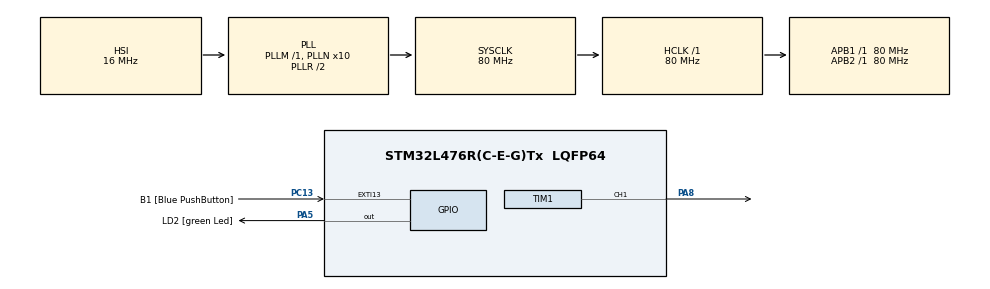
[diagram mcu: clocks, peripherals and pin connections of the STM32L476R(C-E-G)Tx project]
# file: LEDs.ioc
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Dma.Request0=TIM1_CH1
Dma.TIM1_CH1.0.Direction=DMA_MEMORY_TO_PERIPH
Dma.TIM1_CH1.0.Instance=DMA1_Channel2
Dma.TIM1_CH1.0.MemDataAlignment=DMA_MDATAALIGN_HALFWORD
Dma.TIM1_CH1.0.MemInc=DMA_MINC_ENABLE
Dma.TIM1_CH1.0.Mode=DMA_NORMAL
Dma.TIM1_CH1.0.PeriphDataAlignment=DMA_PDATAALIGN_HALFWORD
Dma.TIM1_CH1.0.PeriphInc=DMA_PINC_DISABLE
Dma.TIM1_CH1.0.Priority=DMA_PRIORITY_HIGH
Mcu.Family=STM32L4
Mcu.Name=STM32L476R(C-E-G)Tx
Mcu.Package=LQFP64
NVIC.DMA1_Channel2_IRQn=true\:0\:0\:false\:false\:true\:false\:true\:true
NVIC.PriorityGroup=NVIC_PRIORITYGROUP_4
PA13\ (JTMS-SWDIO).GPIO_Label=TMS
PA13\ (JTMS-SWDIO).Signal=SYS_JTMS-SWDIO
PA14\ (JTCK-SWCLK).GPIO_Label=TCK
PA14\ (JTCK-SWCLK).Signal=SYS_JTCK-SWCLK
PA2.GPIO_Label=USART_TX
PA2.GPIO_Mode=GPIO_MODE_AF_PP
PA2.GPIO_PuPd=GPIO_NOPULL
PA2.GPIO_Speed=GPIO_SPEED_FREQ_VERY_HIGH
PA2.Signal=USART2_TX
PA3.GPIO_Label=USART_RX
PA3.GPIO_Mode=GPIO_MODE_AF_PP
PA3.GPIO_PuPd=GPIO_NOPULL
PA3.GPIO_Speed=GPIO_SPEED_FREQ_VERY_HIGH
PA3.Signal=USART2_RX
PA5.GPIO_Label=LD2 [green Led]
PA5.GPIO_ModeDefaultOutputPP=GPIO_MODE_OUTPUT_PP
PA5.GPIO_PuPd=GPIO_NOPULL
PA5.GPIO_Speed=GPIO_SPEED_FREQ_LOW
PA5.Signal=GPIO_Output
PA8.GPIO_Speed=GPIO_SPEED_FREQ_VERY_HIGH
PA8.Signal=S_TIM1_CH1
PB3\ (JTDO-TRACESWO).GPIO_Label=SWO
PB3\ (JTDO-TRACESWO).Signal=SYS_JTDO-SWO
PC13.GPIO_Label=B1 [Blue PushButton]
PC13.GPIO_ModeDefaultEXTI=GPIO_MODE_IT_FALLING
PC13.GPIO_PuPd=GPIO_NOPULL
PC13.Signal=GPXTI13
PC14-OSC32_IN\ (PC14).Signal=RCC_OSC32_IN
PC15-OSC32_OUT\ (PC15).Signal=RCC_OSC32_OUT
PH0-OSC_IN\ (PH0).Signal=RCC_OSC_IN
PH1-OSC_OUT\ (PH1).Signal=RCC_OSC_OUT
ProjectManager.HeapSize=0x200
ProjectManager.StackSize=0x400
ProjectManager.TargetToolchain=STM32CubeIDE
RCC.ADCFreq_Value=64000000
RCC.AHBFreq_Value=80000000
RCC.APB1Freq_Value=80000000
RCC.APB1TimFreq_Value=80000000
RCC.APB2Freq_Value=80000000
RCC.APB2TimFreq_Value=80000000
RCC.CortexFreq_Value=80000000
RCC.HCLKFreq_Value=80000000
RCC.HSE_VALUE=8000000
RCC.HSI_VALUE=16000000
RCC.LSE_VALUE=32768
RCC.MSI_VALUE=4000000
RCC.PLLN=10
RCC.PLLSourceVirtual=RCC_PLLSOURCE_HSI
RCC.PREFETCH_ENABLE=1
RCC.SYSCLKFreq_VALUE=80000000
RCC.SYSCLKSource=RCC_SYSCLKSOURCE_PLLCLK
RCC.USBFreq_Value=64000000
RCC.VCOOutputFreq_Value=160000000
SH.S_TIM1_CH1.0=TIM1_CH1,PWM Generation1 CH1
TIM1.AutoReloadPreload=TIM_AUTORELOAD_PRELOAD_ENABLE
TIM1.Channel-PWM\ Generation1\ CH1=TIM_CHANNEL_1
TIM1.Period=99
VP_TIM1_VS_ClockSourceINT.Mode=Internal
board=NUCLEO-L476RG

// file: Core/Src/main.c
/* USER CODE BEGIN Header */
/**
  ******************************************************************************
  * @file           : main.c
  * @brief          : Main program body
  ******************************************************************************
  */
/* USER CODE END Header */
#include "main.h"

/* USER CODE BEGIN Includes */
#include <string.h>   // pour memset
/* USER CODE END Includes */

/* USER CODE BEGIN PD */
// === Config NeoPixel ===
#define LED_COUNT    8
#define BITS_PER_LED 24
#define RESET_TICKS  100

// 80 MHz timer -> 1 bit = 1.25 µs = 100 ticks (ARR=99)
#define ARR_VALUE   99
#define T0H_TICKS   32   // ~0.40 µs (bit 0)
#define T1H_TICKS   64   // ~0.80 µs (bit 1)
/* USER CODE END PD */

TIM_HandleTypeDef htim1;
DMA_HandleTypeDef hdma_tim1_ch1;

/* USER CODE BEGIN PV */
static uint16_t pwm_buf[LED_COUNT * BITS_PER_LED + RESET_TICKS];
static uint8_t  leds[LED_COUNT][3]; // [G,R,B]
/* USER CODE END PV */

void SystemClock_Config(void);
static void MX_GPIO_Init(void);
static void MX_DMA_Init(void);
static void MX_TIM1_Init(void);
/* USER CODE BEGIN PFP */
// Fonctions NeoPixel
static void byte_to_pwm(uint8_t byte, uint16_t *out);
void np_set_pixel(uint16_t i, uint8_t r, uint8_t g, uint8_t b);
void np_clear(void);
void np_show(void);
/* USER CODE END PFP */

/* USER CODE BEGIN 0 */
static void byte_to_pwm(uint8_t byte, uint16_t *out)
{
  for (int i = 0; i < 8; i++) {
    out[i] = (byte & (1 << (7 - i))) ? T1H_TICKS : T0H_TICKS;
  }
}

void np_set_pixel(uint16_t i, uint8_t r, uint8_t g, uint8_t b)
{
  if (i >= LED_COUNT) return;
  leds[i][0] = g; // ordre GRB
  leds[i][1] = r;
  leds[i][2] = b;
}

void np_clear(void)
{
  memset(leds, 0, sizeof(leds));
}

void np_show(void)
{
  uint16_t *p = pwm_buf;
  for (int i = 0; i < LED_COUNT; i++) {
    byte_to_pwm(leds[i][0], p); p += 8; // G
    byte_to_pwm(leds[i][1], p); p += 8; // R
    byte_to_pwm(leds[i][2], p); p += 8; // B
  }
  for (int i = 0; i < RESET_TICKS; i++) *p++ = 0;

  __HAL_TIM_SET_AUTORELOAD(&htim1, ARR_VALUE);

  HAL_TIM_PWM_Start_DMA(&htim1, TIM_CHANNEL_1,
                        (uint32_t*)pwm_buf, (uint32_t)(p - pwm_buf));

  // Attendre la fin du DMA
  while (hdma_tim1_ch1.State != HAL_DMA_STATE_READY) { }

  HAL_TIM_PWM_Stop_DMA(&htim1, TIM_CHANNEL_1);
}
/* USER CODE END 0 */

int main(void)
{
  /* MCU Configuration--------------------------------------------------------*/
  HAL_Init();
  SystemClock_Config();
  MX_GPIO_Init();
  MX_DMA_Init();
  MX_TIM1_Init();

  /* USER CODE BEGIN 2 */

  np_clear();
  np_set_pixel(0, 255,   0,   0); // Rouge
  np_set_pixel(1,   0, 255,   0); // Vert
  np_set_pixel(2,   0,   0, 255); // Bleu
  np_set_pixel(3, 255, 255,   0); // Jaune
  np_set_pixel(4, 255,   0,   0); // Rouge
  np_set_pixel(5,   0, 255,   0); // Vert
  np_set_pixel(6,   0,   0, 255); // Bleu
  np_set_pixel(7, 255, 255,   0); // Jaune
  np_show();

  /* USER CODE END 2 */

  while (1)
  {
    /* USER CODE BEGIN WHILE */
    // boucle principale
	  for (int pos = 0; pos < LED_COUNT; pos++) {
	    np_clear();

	    // rouge
	    np_set_pixel(pos, 255, 0, 0);
	    np_show();
	    HAL_Delay(200);

	    // vert
	    np_clear();
	    np_set_pixel(pos, 0, 255, 0);
	    np_show();
	    HAL_Delay(200);

	    // bleu
	    np_clear();
	    np_set_pixel(pos, 0, 0, 255);
	    np_show();
	    HAL_Delay(200);
	  }
    /* USER CODE END WHILE */

    /* USER CODE BEGIN 3 */
  }
}

void SystemClock_Config(void)
{
  RCC_OscInitTypeDef RCC_OscInitStruct = {0};
  RCC_ClkInitTypeDef RCC_ClkInitStruct = {0};

  if (HAL_PWREx_ControlVoltageScaling(PWR_REGULATOR_VOLTAGE_SCALE1) != HAL_OK)
  {
    Error_Handler();
  }
  RCC_OscInitStruct.OscillatorType = RCC_OSCILLATORTYPE_HSI;
  RCC_OscInitStruct.HSIState = RCC_HSI_ON;
  RCC_OscInitStruct.HSICalibrationValue = RCC_HSICALIBRATION_DEFAULT;
  RCC_OscInitStruct.PLL.PLLState = RCC_PLL_ON;
  RCC_OscInitStruct.PLL.PLLSource = RCC_PLLSOURCE_HSI;
  RCC_OscInitStruct.PLL.PLLM = 1;
  RCC_OscInitStruct.PLL.PLLN = 10;
  RCC_OscInitStruct.PLL.PLLP = RCC_PLLP_DIV7;
  RCC_OscInitStruct.PLL.PLLQ = RCC_PLLQ_DIV2;
  RCC_OscInitStruct.PLL.PLLR = RCC_PLLR_DIV2;
  if (HAL_RCC_OscConfig(&RCC_OscInitStruct) != HAL_OK)
  {
    Error_Handler();
  }
  RCC_ClkInitStruct.ClockType = RCC_CLOCKTYPE_HCLK|RCC_CLOCKTYPE_SYSCLK
                              |RCC_CLOCKTYPE_PCLK1|RCC_CLOCKTYPE_PCLK2;
  RCC_ClkInitStruct.SYSCLKSource = RCC_SYSCLKSOURCE_PLLCLK;
  RCC_ClkInitStruct.AHBCLKDivider = RCC_SYSCLK_DIV1;
  RCC_ClkInitStruct.APB1CLKDivider = RCC_HCLK_DIV1;
  RCC_ClkInitStruct.APB2CLKDivider = RCC_HCLK_DIV1;

  if (HAL_RCC_ClockConfig(&RCC_ClkInitStruct, FLASH_LATENCY_4) != HAL_OK)
  {
    Error_Handler();
  }
}

static void MX_TIM1_Init(void)
{
  TIM_ClockConfigTypeDef sClockSourceConfig = {0};
  TIM_MasterConfigTypeDef sMasterConfig = {0};
  TIM_OC_InitTypeDef sConfigOC = {0};
  TIM_BreakDeadTimeConfigTypeDef sBreakDeadTimeConfig = {0};

  htim1.Instance = TIM1;
  htim1.Init.Prescaler = 0;
  htim1.Init.CounterMode = TIM_COUNTERMODE_UP;
  htim1.Init.Period = 99;
  htim1.Init.ClockDivision = TIM_CLOCKDIVISION_DIV1;
  htim1.Init.RepetitionCounter = 0;
  htim1.Init.AutoReloadPreload = TIM_AUTORELOAD_PRELOAD_ENABLE;
  if (HAL_TIM_Base_Init(&htim1) != HAL_OK) Error_Handler();
  sClockSourceConfig.ClockSource = TIM_CLOCKSOURCE_INTERNAL;
  if (HAL_TIM_ConfigClockSource(&htim1, &sClockSourceConfig) != HAL_OK) Error_Handler();
  if (HAL_TIM_PWM_Init(&htim1) != HAL_OK) Error_Handler();
  sMasterConfig.MasterOutputTrigger = TIM_TRGO_RESET;
  sMasterConfig.MasterOutputTrigger2 = TIM_TRGO2_RESET;
  sMasterConfig.MasterSlaveMode = TIM_MASTERSLAVEMODE_DISABLE;
  if (HAL_TIMEx_MasterConfigSynchronization(&htim1, &sMasterConfig) != HAL_OK) Error_Handler();
  sConfigOC.OCMode = TIM_OCMODE_PWM1;
  sConfigOC.Pulse = 0;
  sConfigOC.OCPolarity = TIM_OCPOLARITY_HIGH;
  sConfigOC.OCNPolarity = TIM_OCNPOLARITY_HIGH;
  sConfigOC.OCFastMode = TIM_OCFAST_DISABLE;
  sConfigOC.OCIdleState = TIM_OCIDLESTATE_RESET;
  sConfigOC.OCNIdleState = TIM_OCNIDLESTATE_RESET;
  if (HAL_TIM_PWM_ConfigChannel(&htim1, &sConfigOC, TIM_CHANNEL_1) != HAL_OK) Error_Handler();
  sBreakDeadTimeConfig.OffStateRunMode = TIM_OSSR_DISABLE;
  sBreakDeadTimeConfig.OffStateIDLEMode = TIM_OSSI_DISABLE;
  sBreakDeadTimeConfig.LockLevel = TIM_LOCKLEVEL_OFF;
  sBreakDeadTimeConfig.DeadTime = 0;
  sBreakDeadTimeConfig.BreakState = TIM_BREAK_DISABLE;
  sBreakDeadTimeConfig.BreakPolarity = TIM_BREAKPOLARITY_HIGH;
  sBreakDeadTimeConfig.BreakFilter = 0;
  sBreakDeadTimeConfig.Break2State = TIM_BREAK2_DISABLE;
  sBreakDeadTimeConfig.Break2Polarity = TIM_BREAK2POLARITY_HIGH;
  sBreakDeadTimeConfig.Break2Filter = 0;
  sBreakDeadTimeConfig.AutomaticOutput = TIM_AUTOMATICOUTPUT_DISABLE;
  if (HAL_TIMEx_ConfigBreakDeadTime(&htim1, &sBreakDeadTimeConfig) != HAL_OK) Error_Handler();

  HAL_TIM_MspPostInit(&htim1);
}

static void MX_DMA_Init(void)
{
  __HAL_RCC_DMA1_CLK_ENABLE();
  HAL_NVIC_SetPriority(DMA1_Channel2_IRQn, 0, 0);
  HAL_NVIC_EnableIRQ(DMA1_Channel2_IRQn);
}

static void MX_GPIO_Init(void)
{
  GPIO_InitTypeDef GPIO_InitStruct = {0};
  __HAL_RCC_GPIOC_CLK_ENABLE();
  __HAL_RCC_GPIOH_CLK_ENABLE();
  __HAL_RCC_GPIOA_CLK_ENABLE();
  __HAL_RCC_GPIOB_CLK_ENABLE();

  // Exemple: LED verte LD2
  HAL_GPIO_WritePin(LD2_GPIO_Port, LD2_Pin, GPIO_PIN_RESET);
  GPIO_InitStruct.Pin = LD2_Pin;
  GPIO_InitStruct.Mode = GPIO_MODE_OUTPUT_PP;
  GPIO_InitStruct.Pull = GPIO_NOPULL;
  GPIO_InitStruct.Speed = GPIO_SPEED_FREQ_LOW;
  HAL_GPIO_Init(LD2_GPIO_Port, &GPIO_InitStruct);
}

void Error_Handler(void)
{
  __disable_irq();
  while (1) { }
}
